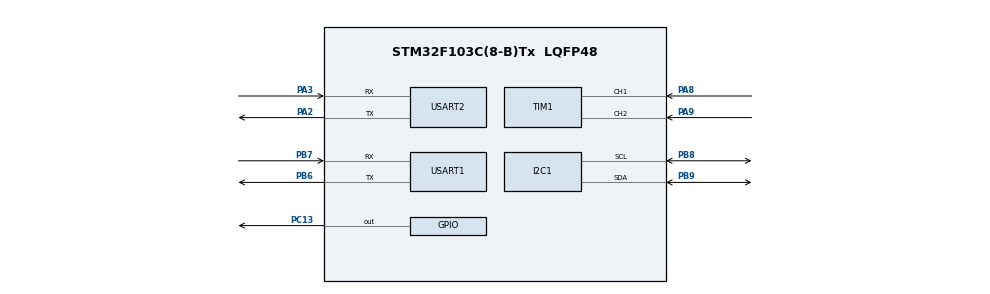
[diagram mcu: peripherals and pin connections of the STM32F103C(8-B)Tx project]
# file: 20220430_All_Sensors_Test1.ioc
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I2C1.I2C_Mode=I2C_Standard
Mcu.Family=STM32F1
Mcu.Name=STM32F103C(8-B)Tx
Mcu.Package=LQFP48
NVIC.PriorityGroup=NVIC_PRIORITYGROUP_4
NVIC.TIM3_IRQn=true\:0\:0\:false\:false\:true\:true\:true
NVIC.USART1_IRQn=true\:0\:0\:false\:false\:true\:true\:true
PA13.Mode=Serial_Wire
PA13.Signal=SYS_JTMS-SWDIO
PA14.Mode=Serial_Wire
PA14.Signal=SYS_JTCK-SWCLK
PA2.Mode=Asynchronous
PA2.Signal=USART2_TX
PA3.Mode=Asynchronous
PA3.Signal=USART2_RX
PA8.GPIO_PuPd=GPIO_PULLUP
PA8.Signal=S_TIM1_CH1
PA9.GPIO_PuPd=GPIO_PULLUP
PA9.Signal=S_TIM1_CH2
PB6.Mode=Asynchronous
PB6.Signal=USART1_TX
PB7.Mode=Asynchronous
PB7.Signal=USART1_RX
PB8.Mode=I2C
PB8.Signal=I2C1_SCL
PB9.Mode=I2C
PB9.Signal=I2C1_SDA
PC13-TAMPER-RTC.Signal=GPIO_Output
PC14-OSC32_IN.Mode=LSE-External-Oscillator
PC14-OSC32_IN.Signal=RCC_OSC32_IN
PC15-OSC32_OUT.Mode=LSE-External-Oscillator
PC15-OSC32_OUT.Signal=RCC_OSC32_OUT
PD0-OSC_IN.Mode=HSE-External-Oscillator
PD0-OSC_IN.Signal=RCC_OSC_IN
PD1-OSC_OUT.Mode=HSE-External-Oscillator
PD1-OSC_OUT.Signal=RCC_OSC_OUT
ProjectManager.HeapSize=0x200
ProjectManager.StackSize=0x400
ProjectManager.TargetToolchain=STM32CubeIDE
RCC.APB1Freq_Value=8000000
RCC.APB2Freq_Value=8000000
RCC.SYSCLKSource=RCC_SYSCLKSOURCE_HSE
SH.S_TIM1_CH1.0=TIM1_CH1,Encoder_Interface
SH.S_TIM1_CH2.0=TIM1_CH2,Encoder_Interface
TIM1.AutoReloadPreload=TIM_AUTORELOAD_PRELOAD_ENABLE
TIM1.EncoderMode=TIM_ENCODERMODE_TI12
TIM1.IC1Filter=15
TIM1.IC2Filter=15
TIM3.AutoReloadPreload=TIM_AUTORELOAD_PRELOAD_ENABLE
USART1.Parity=PARITY_EVEN
USART1.StopBits=STOPBITS_1
USART1.VirtualMode=VM_ASYNC
USART2.VirtualMode=VM_ASYNC
VP_TIM3_VS_ClockSourceINT.Mode=Internal
board=custom

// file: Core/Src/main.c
/* USER CODE BEGIN Header */
/**
  ******************************************************************************
  * @file           : main.c
  * @brief          : Main program body
  ******************************************************************************
  * @attention
  *
  * Copyright (c) 2022 STMicroelectronics.
  * All rights reserved.
  *
  * This software is licensed under terms that can be found in the LICENSE file
  * in the root directory of this software component.
  * If no LICENSE file comes with this software, it is provided AS-IS.
  *
  ******************************************************************************
  */
/* USER CODE END Header */
#include "main.h"
#include "i2c.h"
#include "tim.h"
#include "usart.h"
#include "gpio.h"

/* USER CODE BEGIN Includes */
#include "analysis.h"
/* USER CODE END Includes */

/* USER CODE BEGIN PM */
extern char bufferRX[RX_SIZE];
extern char bufferTX[TX_SIZE];
/* USER CODE END PM */

void SystemClock_Config(void);

int main(void)
{

  /* MCU Configuration--------------------------------------------------------*/

  /* Reset of all peripherals, Initializes the Flash interface and the Systick. */
  HAL_Init();

  /* Configure the system clock */
  SystemClock_Config();

  /* Initialize all configured peripherals */
  MX_GPIO_Init();
  MX_I2C1_Init();
  MX_TIM1_Init();
  MX_TIM3_Init();
  MX_USART1_UART_Init();
  MX_USART2_UART_Init();
  /* USER CODE BEGIN 2 */
  //HAL_ROTARY_Start(&htim1, &htim3, 8000);
  HAL_UART_Receive_IT(&huart1, bufferRX, sizeof(bufferRX));
  //  HAL_IMU_Init(&hi2c1);
  /* USER CODE END 2 */

  /* Infinite loop */
  while (1)
  {

    /* USER CODE BEGIN 3 */
//	  HAL_IMU_Read(&hi2c1, &himu);
		 // ToDo: will be moved into CallRX

  }
  /* USER CODE END 3 */
}

void SystemClock_Config(void)
{
  RCC_OscInitTypeDef RCC_OscInitStruct = {0};
  RCC_ClkInitTypeDef RCC_ClkInitStruct = {0};

  /** Initializes the RCC Oscillators according to the specified parameters
  * in the RCC_OscInitTypeDef structure.
  */
  RCC_OscInitStruct.OscillatorType = RCC_OSCILLATORTYPE_HSE;
  RCC_OscInitStruct.HSEState = RCC_HSE_ON;
  RCC_OscInitStruct.PLL.PLLState = RCC_PLL_NONE;
  if (HAL_RCC_OscConfig(&RCC_OscInitStruct) != HAL_OK)
  {
    Error_Handler();
  }
  /** Initializes the CPU, AHB and APB buses clocks
  */
  RCC_ClkInitStruct.ClockType = RCC_CLOCKTYPE_HCLK|RCC_CLOCKTYPE_SYSCLK
                              |RCC_CLOCKTYPE_PCLK1|RCC_CLOCKTYPE_PCLK2;
  RCC_ClkInitStruct.SYSCLKSource = RCC_SYSCLKSOURCE_HSE;
  RCC_ClkInitStruct.AHBCLKDivider = RCC_SYSCLK_DIV1;
  RCC_ClkInitStruct.APB1CLKDivider = RCC_HCLK_DIV1;
  RCC_ClkInitStruct.APB2CLKDivider = RCC_HCLK_DIV1;

  if (HAL_RCC_ClockConfig(&RCC_ClkInitStruct, FLASH_LATENCY_0) != HAL_OK)
  {
    Error_Handler();
  }
}

void Error_Handler(void)
{
  /* USER CODE BEGIN Error_Handler_Debug */
  /* User can add his own implementation to report the HAL error return state */
  __disable_irq();
  while (1)
  {
	  HAL_GPIO_WritePin(GPIOC, GPIO_PIN_13, GPIO_PIN_SET);
  }
  /* USER CODE END Error_Handler_Debug */
}
